VERSION ""

NS_ :

BS_:

BU_: REAR_BOX

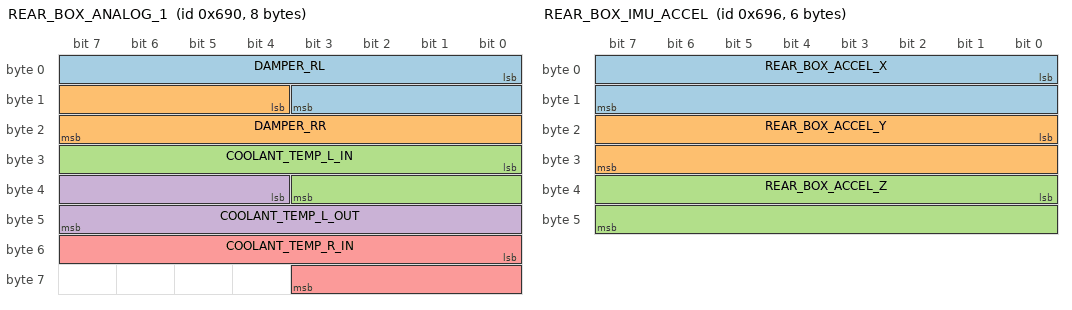
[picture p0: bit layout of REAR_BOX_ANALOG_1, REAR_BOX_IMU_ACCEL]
BO_ 1680 REAR_BOX_ANALOG_1: 8 REAR_BOX
 SG_ DAMPER_RL : 0|12@1+ (0.0008058608058608059,0) [0|3.3] "V" Vector__XXX
 SG_ DAMPER_RR : 12|12@1+ (0.0008058608058608059,0) [0|3.3] "V" Vector__XXX
 SG_ COOLANT_TEMP_L_IN : 24|12@1+ (0.0008058608058608059,0) [0|3.3] "V" Vector__XXX
 SG_ COOLANT_TEMP_L_OUT : 36|12@1+ (0.0008058608058608059,0) [0|3.3] "V" Vector__XXX
 SG_ COOLANT_TEMP_R_IN : 48|12@1+ (0.0008058608058608059,0) [0|3.3] "V" Vector__XXX

BO_ 1681 REAR_BOX_ANALOG_2: 2 REAR_BOX
 SG_ COOLANT_TEMP_R_OUT : 0|12@1+ (0.0008058608058608059,0) [0|3.3] "V" Vector__XXX

BO_ 1685 REAR_BOX_DIGITAL: 1 REAR_BOX
 SG_ FAN_L_TACH : 0|1@1+ (1,0) [0|1] "bool" Vector__XXX
 SG_ FAN_R_TACH : 1|1@1+ (1,0) [0|1] "bool" Vector__XXX

BO_ 1686 REAR_BOX_IMU_ACCEL: 6 REAR_BOX
 SG_ REAR_BOX_ACCEL_X : 0|16@1- (0.000122,0) [-4|4] "g" Vector__XXX
 SG_ REAR_BOX_ACCEL_Y : 16|16@1- (0.000122,0) [-4|4] "g" Vector__XXX
 SG_ REAR_BOX_ACCEL_Z : 32|16@1- (0.000122,0) [-4|4] "g" Vector__XXX

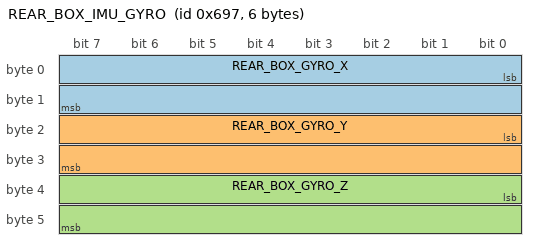
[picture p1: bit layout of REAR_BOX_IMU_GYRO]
BO_ 1687 REAR_BOX_IMU_GYRO: 6 REAR_BOX
 SG_ REAR_BOX_GYRO_X : 0|16@1- (0.0175,0) [-500|500] "dps" Vector__XXX
 SG_ REAR_BOX_GYRO_Y : 16|16@1- (0.0175,0) [-500|500] "dps" Vector__XXX
 SG_ REAR_BOX_GYRO_Z : 32|16@1- (0.0175,0) [-500|500] "dps" Vector__XXX

BO_ 1688 REAR_BOX_TEMP: 4 REAR_BOX
 SG_ REAR_BOX_IMU_TEMP : 0|16@1- (0.00390625,25) [-40|85] "degC" Vector__XXX
 SG_ REAR_BOX_AMBIENT_TEMP : 16|16@1- (0.0625,0) [-55|125] "degC" Vector__XXX

BO_ 1689 REAR_BOX_STATUS: 1 REAR_BOX
 SG_ REAR_BOX_ISM330_OK : 0|1@1+ (1,0) [0|1] "" Vector__XXX
 SG_ REAR_BOX_MCP9800_OK : 1|1@1+ (1,0) [0|1] "" Vector__XXX
